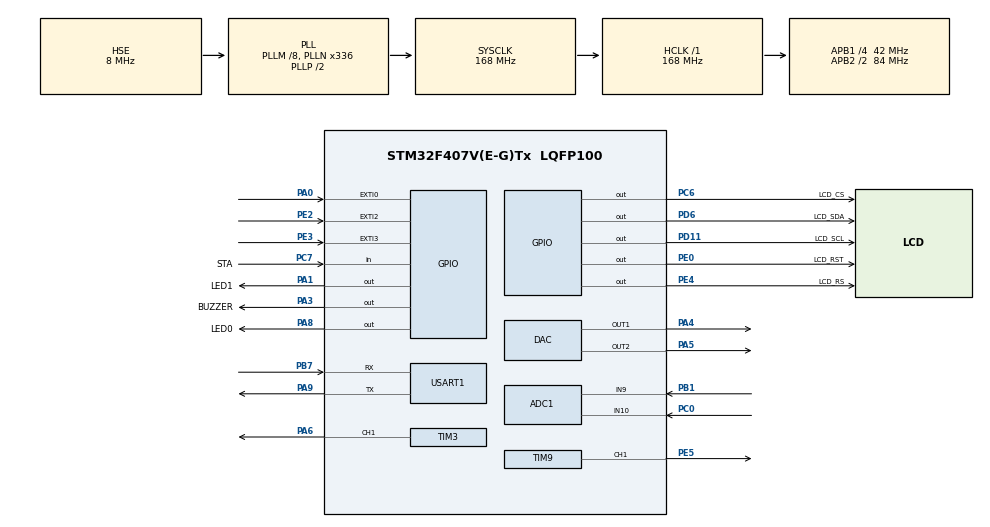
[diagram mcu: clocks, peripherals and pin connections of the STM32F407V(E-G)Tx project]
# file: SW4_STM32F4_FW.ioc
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ADC1.Channel-0\#ChannelRegularConversion=ADC_CHANNEL_9
ADC1.Channel-1\#ChannelRegularConversion=ADC_CHANNEL_10
ADC1.Channel-2\#ChannelRegularConversion=ADC_CHANNEL_TEMPSENSOR
ADC1.ContinuousConvMode=ENABLE
ADC1.DMAContinuousRequests=ENABLE
ADC1.NbrOfConversion=3
ADC1.NbrOfConversionFlag=1
ADC1.Rank-0\#ChannelRegularConversion=1
ADC1.Rank-1\#ChannelRegularConversion=2
ADC1.Rank-2\#ChannelRegularConversion=3
ADC1.SamplingTime-0\#ChannelRegularConversion=ADC_SAMPLETIME_3CYCLES
ADC1.SamplingTime-1\#ChannelRegularConversion=ADC_SAMPLETIME_3CYCLES
ADC1.SamplingTime-2\#ChannelRegularConversion=ADC_SAMPLETIME_3CYCLES
ADC1.ScanConvMode=ENABLE
ADC1.master=1
DAC.DAC_Trigger=DAC_TRIGGER_T6_TRGO
DAC.DAC_Trigger2=DAC_TRIGGER_T6_TRGO
DAC.TriangleAmplitude=DAC_TRIANGLEAMPLITUDE_255
DAC.WaveGeneration=TriangleWaveGeneration
Dma.ADC1.0.Direction=DMA_PERIPH_TO_MEMORY
Dma.ADC1.0.FIFOMode=DMA_FIFOMODE_DISABLE
Dma.ADC1.0.Instance=DMA2_Stream0
Dma.ADC1.0.MemDataAlignment=DMA_MDATAALIGN_HALFWORD
Dma.ADC1.0.MemInc=DMA_MINC_ENABLE
Dma.ADC1.0.Mode=DMA_NORMAL
Dma.ADC1.0.PeriphDataAlignment=DMA_PDATAALIGN_HALFWORD
Dma.ADC1.0.PeriphInc=DMA_PINC_DISABLE
Dma.ADC1.0.Priority=DMA_PRIORITY_LOW
Dma.DAC1.1.Direction=DMA_MEMORY_TO_PERIPH
Dma.DAC1.1.FIFOMode=DMA_FIFOMODE_DISABLE
Dma.DAC1.1.Instance=DMA1_Stream5
Dma.DAC1.1.MemDataAlignment=DMA_MDATAALIGN_HALFWORD
Dma.DAC1.1.MemInc=DMA_MINC_ENABLE
Dma.DAC1.1.Mode=DMA_NORMAL
Dma.DAC1.1.PeriphDataAlignment=DMA_PDATAALIGN_HALFWORD
Dma.DAC1.1.PeriphInc=DMA_PINC_DISABLE
Dma.DAC1.1.Priority=DMA_PRIORITY_MEDIUM
Dma.DAC2.2.Direction=DMA_MEMORY_TO_PERIPH
Dma.DAC2.2.FIFOMode=DMA_FIFOMODE_DISABLE
Dma.DAC2.2.Instance=DMA1_Stream6
Dma.DAC2.2.MemDataAlignment=DMA_MDATAALIGN_HALFWORD
Dma.DAC2.2.MemInc=DMA_MINC_ENABLE
Dma.DAC2.2.Mode=DMA_CIRCULAR
Dma.DAC2.2.PeriphDataAlignment=DMA_PDATAALIGN_HALFWORD
Dma.DAC2.2.PeriphInc=DMA_PINC_DISABLE
Dma.DAC2.2.Priority=DMA_PRIORITY_MEDIUM
Dma.Request0=ADC1
Dma.Request1=DAC1
Dma.Request2=DAC2
Mcu.Family=STM32F4
Mcu.Name=STM32F407V(E-G)Tx
Mcu.Package=LQFP100
NVIC.ADC_IRQn=true\:1\:0\:true\:false\:true\:true\:true
NVIC.DMA1_Stream5_IRQn=true\:1\:0\:true\:false\:true\:false\:true
NVIC.DMA1_Stream6_IRQn=true\:0\:0\:false\:false\:true\:false\:true
NVIC.DMA2_Stream0_IRQn=true\:1\:0\:true\:false\:true\:false\:true
NVIC.EXTI0_IRQn=true\:1\:0\:true\:false\:true\:true\:true
NVIC.EXTI2_IRQn=true\:1\:0\:true\:false\:true\:true\:true
NVIC.EXTI3_IRQn=true\:1\:0\:true\:false\:true\:true\:true
NVIC.PriorityGroup=NVIC_PRIORITYGROUP_4
NVIC.TIM1_BRK_TIM9_IRQn=true\:1\:0\:true\:false\:true\:true\:true
NVIC.TIM3_IRQn=true\:1\:0\:true\:false\:true\:true\:true
NVIC.USART1_IRQn=true\:2\:0\:true\:false\:true\:true\:true
PA0-WKUP.GPIO_PuPd=GPIO_PULLDOWN
PA0-WKUP.Signal=GPXTI0
PA1.GPIO_Label=LED1
PA1.GPIO_PuPd=GPIO_PULLDOWN
PA1.PinState=GPIO_PIN_SET
PA1.Signal=GPIO_Output
PA13.Mode=Serial_Wire
PA13.Signal=SYS_JTMS-SWDIO
PA14.Mode=Serial_Wire
PA14.Signal=SYS_JTCK-SWCLK
PA3.GPIO_Label=BUZZER
PA3.GPIO_Speed=GPIO_SPEED_FREQ_VERY_HIGH
PA3.PinState=GPIO_PIN_RESET
PA3.Signal=GPIO_Output
PA4.Signal=COMP_DAC1_group
PA5.Signal=COMP_DAC2_group
PA6.Signal=S_TIM3_CH1
PA8.GPIO_Label=LED0
PA8.GPIO_PuPd=GPIO_PULLDOWN
PA8.PinState=GPIO_PIN_SET
PA8.Signal=GPIO_Output
PA9.Mode=Asynchronous
PA9.Signal=USART1_TX
PB1.Signal=ADCx_IN9
PB7.Mode=Asynchronous
PB7.Signal=USART1_RX
PC0.Signal=ADCx_IN10
PC14-OSC32_IN.Mode=LSE-External-Oscillator
PC14-OSC32_IN.Signal=RCC_OSC32_IN
PC15-OSC32_OUT.Mode=LSE-External-Oscillator
PC15-OSC32_OUT.Signal=RCC_OSC32_OUT
PC6.GPIO_Label=LCD_CS
PC6.GPIO_PuPd=GPIO_PULLUP
PC6.GPIO_Speed=GPIO_SPEED_FREQ_VERY_HIGH
PC6.PinState=GPIO_PIN_SET
PC6.Signal=GPIO_Output
PC7.GPIO_Label=STA
PC7.Signal=GPIO_Input
PD11.GPIO_Label=LCD_SCL
PD11.GPIO_PuPd=GPIO_PULLUP
PD11.GPIO_Speed=GPIO_SPEED_FREQ_VERY_HIGH
PD11.PinState=GPIO_PIN_SET
PD11.Signal=GPIO_Output
PD6.GPIO_Label=LCD_SDA
PD6.GPIO_PuPd=GPIO_PULLUP
PD6.GPIO_Speed=GPIO_SPEED_FREQ_VERY_HIGH
PD6.PinState=GPIO_PIN_SET
PD6.Signal=GPIO_Output
PE0.GPIO_Label=LCD_RST
PE0.GPIO_PuPd=GPIO_PULLUP
PE0.GPIO_Speed=GPIO_SPEED_FREQ_VERY_HIGH
PE0.PinState=GPIO_PIN_SET
PE0.Signal=GPIO_Output
PE2.GPIO_PuPd=GPIO_PULLUP
PE2.Signal=GPXTI2
PE3.GPIO_PuPd=GPIO_PULLUP
PE3.Signal=GPXTI3
PE4.GPIO_Label=LCD_RS
PE4.GPIO_PuPd=GPIO_PULLUP
PE4.GPIO_Speed=GPIO_SPEED_FREQ_VERY_HIGH
PE4.PinState=GPIO_PIN_SET
PE4.Signal=GPIO_Output
PE5.Signal=S_TIM9_CH1
PH0-OSC_IN.Mode=HSE-External-Oscillator
PH0-OSC_IN.Signal=RCC_OSC_IN
PH1-OSC_OUT.Mode=HSE-External-Oscillator
PH1-OSC_OUT.Signal=RCC_OSC_OUT
ProjectManager.HeapSize=0x200
ProjectManager.StackSize=0x400
ProjectManager.TargetToolchain=SW4STM32
RCC.48MHZClocksFreq_Value=84000000
RCC.AHBFreq_Value=168000000
RCC.APB1CLKDivider=RCC_HCLK_DIV4
RCC.APB1Freq_Value=42000000
RCC.APB1TimFreq_Value=84000000
RCC.APB2CLKDivider=RCC_HCLK_DIV2
RCC.APB2Freq_Value=84000000
RCC.APB2TimFreq_Value=168000000
RCC.CortexFreq_Value=168000000
RCC.HCLKFreq_Value=168000000
RCC.HSE_VALUE=8000000
RCC.HSI_VALUE=16000000
RCC.PLLM=8
RCC.PLLN=336
RCC.PLLSourceVirtual=RCC_PLLSOURCE_HSE
RCC.SYSCLKFreq_VALUE=168000000
RCC.SYSCLKSource=RCC_SYSCLKSOURCE_PLLCLK
RCC.VCOOutputFreq_Value=336000000
SH.ADCx_IN10.0=ADC1_IN10,IN10
SH.ADCx_IN9.0=ADC1_IN9,IN9
SH.COMP_DAC1_group.0=DAC_OUT1,DAC_OUT1
SH.COMP_DAC2_group.0=DAC_OUT2,DAC_OUT2
SH.S_TIM3_CH1.0=TIM3_CH1,PWM Generation1 CH1
SH.S_TIM9_CH1.0=TIM9_CH1,PWM Generation1 CH1
TIM3.Channel-PWM\ Generation1\ CH1=TIM_CHANNEL_1
TIM3.Channel-PWM\ Generation2\ No\ Output=TIM_CHANNEL_2
TIM3.Period=999
TIM3.Prescaler=83
TIM6.AutoReloadPreload=TIM_AUTORELOAD_PRELOAD_ENABLE
TIM6.Period=40
TIM6.TIM_MasterOutputTrigger=TIM_TRGO_UPDATE
TIM9.Channel-PWM\ Generation1\ CH1=TIM_CHANNEL_1
TIM9.Period=99
TIM9.Prescaler=167
TIM9.Pulse-PWM\ Generation1\ CH1=99
USART1.VirtualMode=VM_ASYNC
VP_ADC1_TempSens_Input.Mode=IN-TempSens
VP_TIM3_VS_ClockSourceINT.Mode=Internal
VP_TIM3_VS_no_output2.Mode=PWM Generation2 No Output
VP_TIM6_VS_ClockSourceINT.Mode=Enable_Timer
VP_TIM9_VS_ClockSourceINT.Mode=Internal
board=custom

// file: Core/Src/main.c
/* USER CODE BEGIN Header */

/* USER CODE END Header */
#include "main.h"
#include "adc.h"
#include "dac.h"
#include "dma.h"
#include "tim.h"
#include "usart.h"
#include "gpio.h"

/* USER CODE BEGIN Includes */
#include "first_init.h"
/* USER CODE END Includes */

void SystemClock_Config(void);

int main(void)
{

  /* MCU Configuration--------------------------------------------------------*/

  /* Reset of all peripherals, Initializes the Flash interface and the Systick. */
  HAL_Init();

  /* Configure the system clock */
  SystemClock_Config();

  /* Initialize all configured peripherals */
  MX_GPIO_Init();
  MX_DMA_Init();
  MX_ADC1_Init();
  MX_DAC_Init();
  MX_TIM6_Init();
  MX_TIM3_Init();
  MX_TIM9_Init();
  MX_USART1_UART_Init();
  /* USER CODE BEGIN 2 */
    first_init();
  /* USER CODE END 2 */

  /* Infinite loop */
    while (1)
    {

    /* USER CODE BEGIN 3 */
        //任务选择
        if (task < 8)
        {
            main_task(task, back, enter);
        } else
        {
            task = 0;
        }
    }
  /* USER CODE END 3 */
}

void SystemClock_Config(void)
{
  RCC_OscInitTypeDef RCC_OscInitStruct = {0};
  RCC_ClkInitTypeDef RCC_ClkInitStruct = {0};

  /** Configure the main internal regulator output voltage
  */
  __HAL_RCC_PWR_CLK_ENABLE();
  __HAL_PWR_VOLTAGESCALING_CONFIG(PWR_REGULATOR_VOLTAGE_SCALE1);
  /** Initializes the RCC Oscillators according to the specified parameters
  * in the RCC_OscInitTypeDef structure.
  */
  RCC_OscInitStruct.OscillatorType = RCC_OSCILLATORTYPE_HSE;
  RCC_OscInitStruct.HSEState = RCC_HSE_ON;
  RCC_OscInitStruct.PLL.PLLState = RCC_PLL_ON;
  RCC_OscInitStruct.PLL.PLLSource = RCC_PLLSOURCE_HSE;
  RCC_OscInitStruct.PLL.PLLM = 8;
  RCC_OscInitStruct.PLL.PLLN = 336;
  RCC_OscInitStruct.PLL.PLLP = RCC_PLLP_DIV2;
  RCC_OscInitStruct.PLL.PLLQ = 4;
  if (HAL_RCC_OscConfig(&RCC_OscInitStruct) != HAL_OK)
  {
    Error_Handler();
  }
  /** Initializes the CPU, AHB and APB buses clocks
  */
  RCC_ClkInitStruct.ClockType = RCC_CLOCKTYPE_HCLK|RCC_CLOCKTYPE_SYSCLK
                              |RCC_CLOCKTYPE_PCLK1|RCC_CLOCKTYPE_PCLK2;
  RCC_ClkInitStruct.SYSCLKSource = RCC_SYSCLKSOURCE_PLLCLK;
  RCC_ClkInitStruct.AHBCLKDivider = RCC_SYSCLK_DIV1;
  RCC_ClkInitStruct.APB1CLKDivider = RCC_HCLK_DIV4;
  RCC_ClkInitStruct.APB2CLKDivider = RCC_HCLK_DIV2;

  if (HAL_RCC_ClockConfig(&RCC_ClkInitStruct, FLASH_LATENCY_5) != HAL_OK)
  {
    Error_Handler();
  }
}

void Error_Handler(void)
{
    __disable_irq();
    while (1)
    {
    }
}

/************************ (C) COPYRIGHT STMicroelectronics *****END OF FILE****/
